# D1H register map
Vendor: Allwinner; File version: 1.0
Registers are 32-bit, read-write, reset 0x0 unless marked. A register's access mark holds for its fields unless they carry their own. Offsets are from the block's base; [hi:lo] are bit positions; {n}, {i} and the like mark numbered series; 'fields as' and 'values as' point back to an identical list.

## TVE — TV Encoder
Base 0x05604000
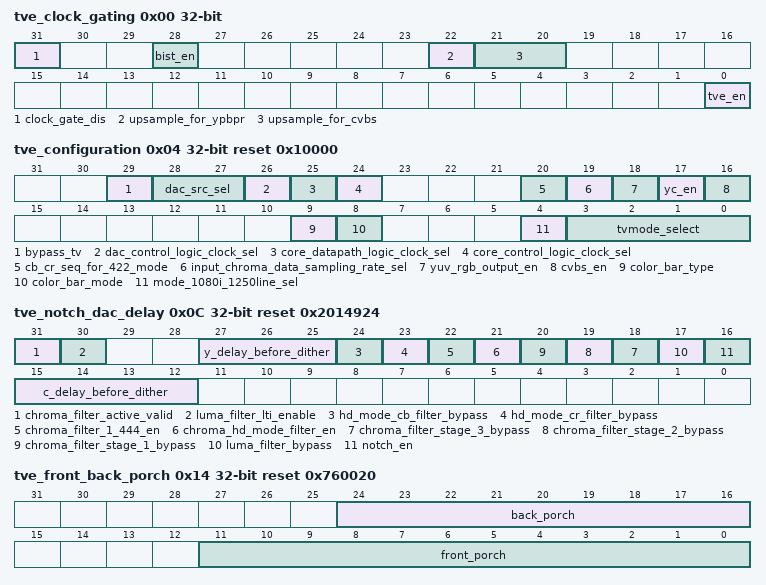
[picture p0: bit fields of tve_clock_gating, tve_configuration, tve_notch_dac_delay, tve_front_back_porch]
0x00 tve_clock_gating — TV Encoder Clock Gating Register
  [31] clock_gate_dis
    0=ENABLE; 1=DISABLE
  [28] bist_en
    0=NORMAL (Normal mode); 1=B_IST (Bist mode)
  [22] upsample_for_ypbpr
    0=1x; 1=X2 (2x)
  [21:20] upsample_for_cvbs
    0=F27M (27 MHz); 1=F54M (54 MHz); 2=F108M (108 MHz); 3=F216M (216 MHz)
  [0] tve_en — Video Encoder enable, default disable, write 1 to take it out of the reset state
    0=DISABLE; 1=ENABLE
0x04 tve_configuration reset 0x10000 — TV Encoder Configuration Register
  [29] bypass_tv
    0=DISABLE; 1=ENABLE
  [28:27] dac_src_sel
    0=TVE (TV Encoder); 1=LCD_CONTROLLER (LCD controller, override all other TV encoder setting, the DAC clock can from LCD controller.); 2=DAC_TEST (DAC test mode, DAC using DAC clock); 3=DAC_TEST_AHB (DAC test mode, DAC using AHB clock)
  [26] dac_control_logic_clock_sel
    0=27M_74_25M (Using 27 MHz clock or 74.25 MHz clock depend on CCU setting); 1=54M_148_5M (Using 54 MHz clock or 148.5 MHz clock depend on CCU setting)
  [25] core_datapath_logic_clock_sel
    values as dac_control_logic_clock_sel
  [24] core_control_logic_clock_sel
    values as dac_control_logic_clock_sel
  [20] cb_cr_seq_for_422_mode
    0=C_B (Cb first); 1=C_R (Cr first)
  [19] input_chroma_data_sampling_rate_sel
    0=4_4_4; 1=4_2_2
  [18] yuv_rgb_output_en
    0=CVBS
  [17] yc_en — S-port Video enable Selection. . This bit selects whether the S-port(Y/C) video output is enabled or disabled.
    0=Y_C (Y/C is disable)
  [16] cvbs_en — Composite video enables selection . This bit selects whether the composite video output (CVBS) is enabled or disabled.
    0=DISABLED (Composite video is disabled, Only Y/C is enabled); 1=ENABLED (Composite video is enabled., CVBS and Y/C are enabled)
  [9] color_bar_type
    0=75/7.5/75/7.5 (NTSC), 100/0/75/0(PAL); 1=100/7.5/100/7.5(NTSC), 100/0/100/0(PAL)
  [8] color_bar_mode — Standard Color bar input selection . This bit selects whether the Video Encoder video data input is replaced by an internal standard color bar generator or not.
    0=D_ISPLAY_E_NGINEER (The Video Encoder input is coming from the Display Engineer); 1=I_NTERNAL_GENERATOR (The Video Encoder input is coming from an internal standard color bar generator.)
  [4] mode_1080i_1250line_sel
    0=1125 Line mode; 1=1250 Line mode
  [3:0] tvmode_select — TVMode_Select . Note: Changing this register value will cause some relative register setting to relative value.
    0=NTSC; 1=PAL
0x08 tve_dac1 — TV Encoder DAC Register1
  [6:4] dac0_src_sel
    0=C_OMPOSITE
0x0C tve_notch_dac_delay reset 0x2014924 (reset mask 0xCFFFFFFF) — TV Encoder Notch and DAC Delay Register
  [31] chroma_filter_active_valid
    0=DISABLE; 1=ENABLE
  [30] luma_filter_lti_enable
    0=DISABLE (Disable Luma filter lti); 1=ENABLE (Enable Luma filter lti)
  [27:25] y_delay_before_dither
  [24] hd_mode_cb_filter_bypass
    0=ENABLE (Bypass Enable); 1=DISABLE (Bypass Disable)
  [23] hd_mode_cr_filter_bypass
    0=ENABLE (Bypass Enable); 1=DISABLE (Bypass Disable)
  [22] chroma_filter_1_444_en
    0=DISABLE (Chroma Filter 1 444 Disable); 1=ENABLE (Chroma Filter 1 444 Enable)
  [21] chroma_hd_mode_filter_en
    0=DISABLE (Chroma HD Filter Disable); 1=ENABLE (Chroma HD Filter Enable)
  [18] chroma_filter_stage_{x}_bypass (x=3,2,1; step 1)
    0=ENABLE (Chroma Filter Stage [i] Enable); 1=BYPASS (Chroma Filter Stage [i] bypass)
  [17] luma_filter_bypass
    0=ENABLE (Luma Filter Enable); 1=BYPASS (Luma Filter bypass)
  [16] notch_en — Luma notch filter on/off selection . Note: This bit selects if the luma notch filter is operating or bypassed.
    0=BYPASSED (The luma notch filter is bypassed); 1=OPERATING (The luma notch filter is operating)
  [15:12] c_delay_before_dither
0x10 tve_chroma_frequency reset 0x21F07C1F — TV Encoder Chroma Frequency Register
  [31:0] chroma_freq — Specify the ratio between the color burst frequency. 32 bits unsigned fraction. The default value is h21f07c1f, which is compatible with NTSC spec.
0x14 tve_front_back_porch reset 0x760020 — TV Encoder Front/Back Porch Register
  [24:16] back_porch — Specify the width of the back porch in encoder clock cycles. Min value is (burst_width+breeze_way+17). 8 bits unsigned integer. . The default value is 118. . For 720p mode, the value is 260. . For 1080i/p mode, the value is 192.
  [11:0] front_porch — Must be even . Specify the width of the front porch in encoder clock cycles. 6 bits unsigned even integer. Allowed range is form 10 to 62. . The default value is 32. . For 1080i mode, the value is 44.
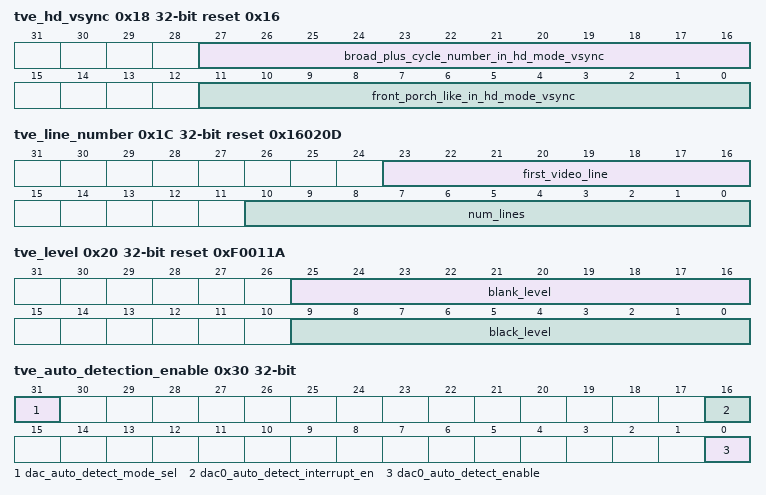
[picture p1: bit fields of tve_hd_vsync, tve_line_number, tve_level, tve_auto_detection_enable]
0x18 tve_hd_vsync reset 0x16 — TV Encoder HD Mode VSYNC Register
  [27:16] broad_plus_cycle_number_in_hd_mode_vsync, [11:0] front_porch_like_in_hd_mode_vsync
0x1C tve_line_number reset 0x16020D — TV Encoder Line Number Register
  [23:16] first_video_line — Specify the index of the first line in a field/frame to have active video. 8 bits unsigned integer. . For interlaced video: When VSync5=B'0', FirstVideoLine is restricted to be greater than 7. When VSync5=B'1', FirstVideoLine is restricted to be greater than 9.
  [10:0] num_lines — Specify the total number of lines in a video frame. 11 bits unsigned integer. Allowed range is 0 to 2048. For interlaced video: When NTSC, and FirstVideoLine is greater than 20, then NumLines is restricted to be greater than 2*(FirstVideoLine+18). . When NTSC, and FirstVideoLine is not greater than 20, then NumLines is restricted to be greater than 77. When PAL, and FirstVideoLine is greater than 22, then NumLines is restricted to be greater than 2*(FirstVideoLine+18). When PAL, and FirstVideoLine is not greater than 22, then NumLines is restricted to be greater than 81. . If NumLines is even, then it is restricted to be divisible by 4. If NumLines is odd, then it is restricted to be divisible by 4 with a remainder of 1.
0x20 tve_level reset 0xF0011A — TV Encoder Level Register
  [25:16] blank_level — Specify the blank level setting for active lines. This is 10 bits unsigned integer. Allowed range is from 0 to 1023.
  [9:0] black_level — Specify the black level setting. This is 10 bits unsigned integer. Allowed range is from 240 to 1023.
0x24 tve_dac2 — TV Encoder DAC Register2
0x30 tve_auto_detection_enable — TV Encoder Auto Detection Enable Register
  [31] dac_auto_detect_mode_sel
    0=O_LD (Old Mode); 1=N_EW (New Mode)
  [16] dac0_auto_detect_interrupt_en
  [0] dac0_auto_detect_enable
0x34 tve_auto_detection_interrupt_status — TV Encoder Auto Detection Interrupt Status Register
  [0] dac0_auto_detect_interrupt_active_flag write-1-clears — Write 1 to inactive DAC0 auto detection interrupt
0x38 tve_auto_detection_status — TV Encoder Auto Detection Status Register
  [1:0] dac0_status ro
    0=U_NCONNECTED; 1=C_ONNECTED; 3=S_HORT_TO_GROUND
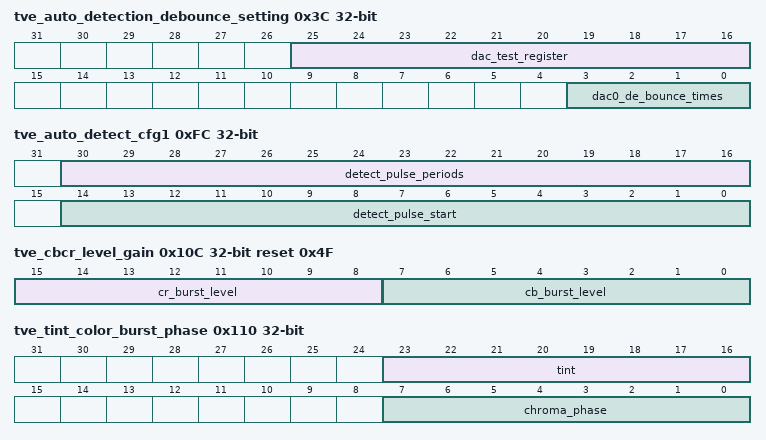
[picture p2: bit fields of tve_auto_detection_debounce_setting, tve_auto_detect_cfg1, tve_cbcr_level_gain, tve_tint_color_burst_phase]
0x3C tve_auto_detection_debounce_setting — TV Encoder Auto Detection De-bounce Setting Register
  [25:16] dac_test_register
  [3:0] dac0_de_bounce_times — The de_bounce time for hot plug detect function.
0xF8 tve_auto_detect_cfg0 — TV Encoder Auto Detect Configuration Register0
  [9:0] detect_pulse_value — Use for DAC data input at auto detect pluse. Set the pulse amplitude.
0xFC tve_auto_detect_cfg1 — TV Encoder Auto Detect Configuration Register1
  [30:16] detect_pulse_periods — Use 32K clock
  [14:0] detect_pulse_start — Detect signal start time
0x100 tve_color_burst_phase_reset_cfg — TV Encoder Color Burst Phase Reset Configuration Register
  [1:0] color_phase_reset — Color burst phase period selection . These bits select the number of fields or lines after which the color burst phase is reset to its initial value as specified by the ChromaPhase parameter, This parameter is application only for interlaced video.
    0=LINE8 (8 field); 1=LINE4 (4 field); 2=LINE2 (2 lines); 3=ONLY_ONCE
0x104 tve_vsync_number — TV Encoder VSYNC Number Register
  [0] vsync5 — VSync5 Number of equalization pulse selection . This bit selects whether the number of equalization pulses is 5 or 6. This parameter is applicable only for interlaced video.
    0=5 equalization pulse(default); 1=6 equalization pulses
0x108 tve_notch_filter_frequency reset 0x2 — TV Encoder Notch Filter Frequency Register
  [2:0] notch_freq — Luma notch filter center frequency selection . These bits select the luma notch filter (which is a band-reject filter) center frequency. In two of the selections, the filter width affects also the selection of the center frequency.
    0=1_1875; 1=1_1406; 2=1.0938. When notch_wide value is B'1' (this selection is proper for CCIR-NTSC), or 1.0000 when notch_wide value is B'0'.; 3=0.9922. This selection is proper for NTSC with square pixels.; 4=0.9531. This selection is proper for PAL with square pixel.; 5=0.8359 when notch_wide value is B'1' (this selection is proper for CCIR-PAL), or 0.7734 when notch_wide value is B'0'; 6=0_7813; 7=0_7188
0x10C tve_cbcr_level_gain reset 0x4F — TV Encoder Cb/Cr Level/Gain Register
  [15:8] cr_burst_level — Specify the amplitude of the Cr burst. 8 bit 2's complement integer. Allowed range is from (-127) to 127.
  [7:0] cb_burst_level — Specify the amplitude of the Cb burst. 8 bit 2's complement integer. Allowed range is from (-127) to 127.
0x110 tve_tint_color_burst_phase — TV Encoder Tint and Color Burst Phase Register
  [23:16] tint — Specify the tint adjustment of the chroma signal for CVBS and Y/C outputs. The adjustment is effected by setting the sub- carrier phase to the value of this parameter. 8.8 bit unsigned fraction. Units are cycles of the color burst frequency.
  [7:0] chroma_phase — Specify the color burst initial phase (ChromaPhase). 8.8 bit unsigned fraction. Units are cycles of the color burst frequency. . The color burst is set to this phase at the first HSYNC and then reset to the same value at further HSYNCs as specified by the CPhaseRset bits of the EncConfig5 parameter (see above)
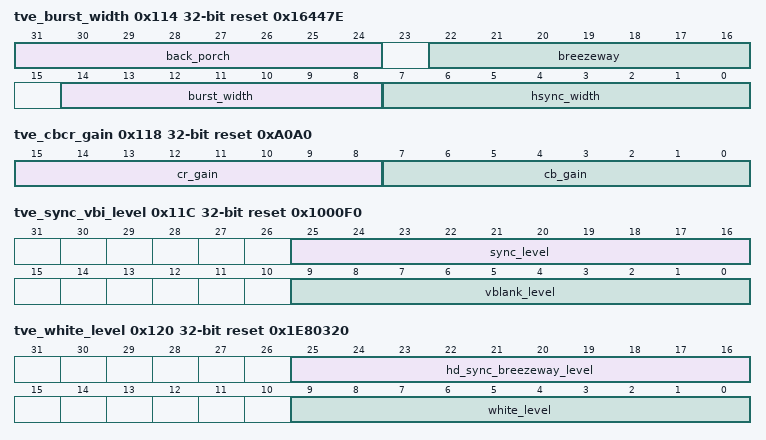
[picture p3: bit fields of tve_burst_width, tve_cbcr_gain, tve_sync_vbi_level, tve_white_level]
0x114 tve_burst_width reset 0x16447E — TV Encoder Burst Width Register
  [31:24] back_porch — Breezeway like in HD mode VSync . For 720p mode, the value is 220 . For 2080i/p mode, the value is 88 (default)
  [22:16] breezeway — Must be even . Specify the width of the breezeway in encoder clock cycles. 5 bit unsigned integer. Allowed range is 0 to 31. . For 1080i mode, the value is 44. . For 1080p mode, the value is 44. . For 720p mode, the value is 40.
  [14:8] burst_width — Specify the width of the color frequency burst in encoder clock cycles. 7 bit unsigned integer. Allowed range is 0 to 127. In hd mode, it is ignored.
  [7:0] hsync_width — Specify the width of the horizontal sync pulse in encoder clock cycles. Min value is 16. Max value is (FrontPorch + ActiveLine - BackPorch). Default value is 126. The sum of HSyncSize and BackPorch is restricted to be divisible by 4. . For 720p mode, the value is 40. . For 1080i/p mode, the value is 44.
0x118 tve_cbcr_gain reset 0xA0A0 — TV Encoder Cb/Cr Gain Register
  [15:8] cr_gain — Specify the Cr color gain. 8-bit unsigned fraction.
  [7:0] cb_gain — Specify the Cb color gain. 8-bit unsigned fraction.
0x11C tve_sync_vbi_level reset 0x1000F0 — TV Encoder Sync and VBI Level Register
  [25:16] sync_level — Specify the sync pulse level setting. 8-bit unsigned integer. Allowed range is from 0 to ABlankLevel-1 or VBlankLevel-1 (whichever is smaller).
  [9:0] vblank_level — Specify the blank level setting for non active lines. 10-bit unsigned integer. Allow range is from 0 to 1023.
0x120 tve_white_level reset 0x1E80320 — TV Encoder White Level Register
  [25:16] hd_sync_breezeway_level — Specify the breezeway level setting. 10-bit unsigned integer. Allowed range is from 0 to 1023.
  [9:0] white_level — Specify the white level setting. 10-bit unsigned integer. Allowed range is from black_level+1 or vbi_blank_level +1 (whichever is greater) to 1023.
0x124 tve_video_active_line reset 0x5A0 — TV Encoder Video Active Line Register
  [11:0] active_line — Specify the width of the video line in encoder clock cycles. 12- bit unsigned multiple of 4 integer. Allowed range is from 0 to 4092.
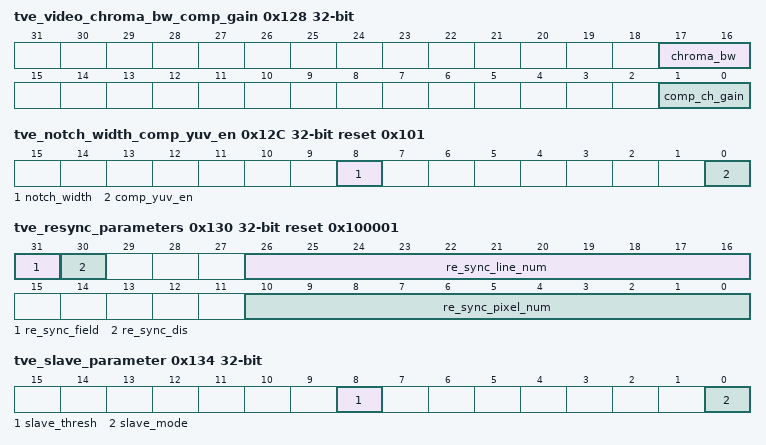
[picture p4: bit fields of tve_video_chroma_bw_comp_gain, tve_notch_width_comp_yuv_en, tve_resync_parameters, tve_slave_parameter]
0x128 tve_video_chroma_bw_comp_gain — TV Encoder Video Chroma BW and CompGain Register
  [17:16] chroma_bw — Chroma filter bandwidth selection . This bit specifies whether the bandwidth of the chroma filter is:
    0=N_ARROW (Narrow width 0.6 MHz); 1=W_IDE (Wide width 1.2 MHz); 2=E_XTRA (Extra width 1.8 MHz); 3=U_LTRA (Ultra width 2.5 MHz)
  [1:0] comp_ch_gain — Chroma gain selection for the composite video signal. . These bits specify the gain of the chroma signal for composing with the luma signal to generate the composite video signal:
    0=100; 1=25; 2=50; 3=75
0x12C tve_notch_width_comp_yuv_en reset 0x101 — TV Encoder Register
  [8] notch_width — Luma notch filter width selection . This bit selects the luma notch filter (which is a band-reject filter) width.
    0=N_ARROW; 1=W_IDE
  [0] comp_yuv_en — This bit selects if the components video output are the RGB components or the YUV components.
    0=RGB (The three component outputs are the RGB components.); 1=YUV (The three component outputs are the YUV components, (i.e. the color conversion unit is bypassed))
0x130 tve_resync_parameters reset 0x100001 — TV Encoder Re-sync Parameters Register
  [31] re_sync_field
  [30] re_sync_dis
    0=ENABLE (Re-Sync Enable); 1=DISABLE (Re-Sync Disable)
  [26:16] re_sync_line_num — Re-sync line number from TCON
  [10:0] re_sync_pixel_num — Re-sync line pixel from TCON
0x134 tve_slave_parameter — TV Encoder Slave Parameter Register
  [8] slave_thresh — Horizontal line adjustment threshold selection . This bit selects whether the number of lines after which the Video Encoder starts the horizontal line length adjustment is slave mode is 0 or 30.
    0=Number of lines is 0; 1=Number of lines is 30
  [0] slave_mode — Slave mode selection . This bit selects whether the Video Encoder is sync slave, partial slave or sync master. It should be set to B'0'.
    0=NOT_FULL_SYNC_SLAVE (The Video Encoder is not a full sync slave (i.e. it is a partial sync slave or a sync master))
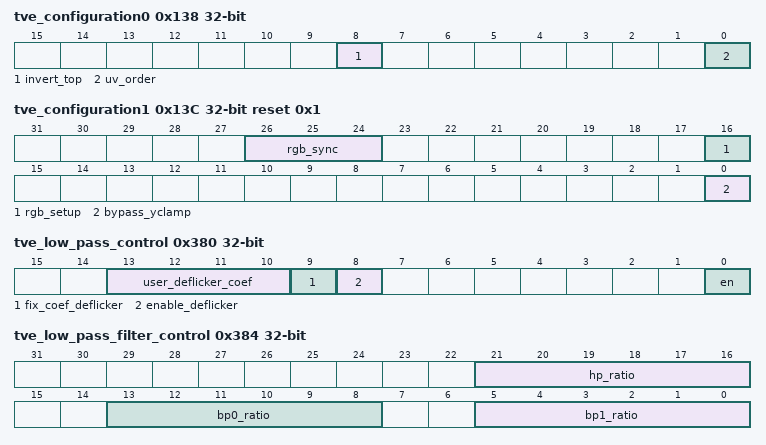
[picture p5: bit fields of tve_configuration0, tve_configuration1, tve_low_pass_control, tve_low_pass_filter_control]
0x138 tve_configuration0 — TV Encoder Configuration Register0
  [8] invert_top — Field parity input signal (top_field) polarity selection. . This bit selects whether the top field is indicated by a high level of the field parity signal or by the low level. The bit is applicable both when the Video Encoder is the sync master and when the Video Encoder is the sync slave.
    0=LOW (Top field is indicated by low level); 1=HIGH (Top field is indicated by high level)
  [0] uv_order — This bit selects if the sample order at the chroma input to the Video Encoder is Cb first (i.e. Cb 0 Cr 0 Cb 1 Cr 1) or Cr first (i.e. Cr 0 Cb 0 Cr 1 Cb 1).
    0=C_B (The chroma sample input order is Cb first); 1=C_R (The chroma sample input order is Cr first)
0x13C tve_configuration1 reset 0x1 — TV Encoder Configuration Register1
  [26:24] rgb_sync — R, G and B signals sync embedding selection. . These bits specify whether the sync signal is added to each of the R, G and B components (b'1') or not (b'0'). The bit[26] specify if the R signal has embedded syncs, the bit[25] specify if the G signal has embedded syncs and the bit[24] specify if the B signal has embedded syncs. When comp_yuv is equal to b'1', these bits are N.A. and should be set to b'000'. When the value is different from b'000', RGB_Setup should be set to b'1'.
  [16] rgb_setup — "Set-up" enable for RGB outputs. This bit specifies if the "set-up" implied value (black_level - blank_level) specified for the CVBS signal is used also for the RGB signals.
    0=NOT_USED (The "set-up" is not used, or i.e. comp_yuv is equal to b'1'.); 1=USED (The implied "set-up" is used for the RGB signals)
  [0] bypass_yclamp — Y input clamping selection . This bit selects whether the Video Encoder Y input is clamped to 64 to 940 or not. When not clamped the expected range is 0 to 1023. The U and V inputs are always clamped to the range 64 to 960.
    0=CLAMPED (The Video Encoder Y input is clamped); 1=NOT_CLAMPED (The Video Encoder Y input is not clamped)
0x380 tve_low_pass_control — TV Encoder Low Pass Control Register
  [13:10] user_deflicker_coef — User_deflicker_coef up: coef/32 . Center: 1-coef/16 . Down: coef/32
  [9] fix_coef_deflicker
    0=A_UTO (Auto deflicker); 1=U_SER (User deflicker)
  [8] enable_deflicker
    0=DISABLE (Disable deflicker); 1=ENABLE (Enable deflicker)
  [0] en — LP function enable
    0=DISABLE; 1=ENABLE
0x384 tve_low_pass_filter_control — TV Encoder Low Pass Filter Control Register
  [21:16] hp_ratio — Default high-pass filter ratio . In two complement, the range is from -31 to 31.
  [13:8] bp0_ratio — Default band-pass filter0 ratio . In two complement, the range is from -31 to 31.
  [5:0] bp1_ratio — Default band-pass filter1 ratio . In two complement, the range is from -31 to 31.
0x388 tve_low_pass_gain — TV Encoder Low Pass Gain Register
  [7:0] gain — Peaking gain setting.
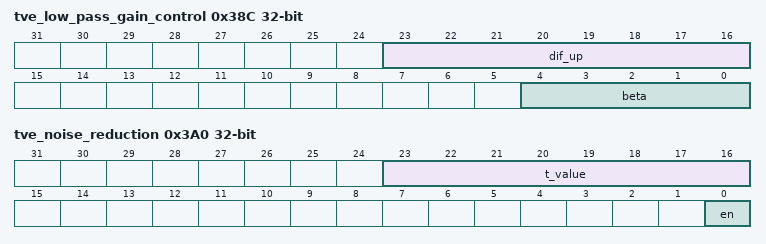
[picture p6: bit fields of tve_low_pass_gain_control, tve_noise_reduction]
0x38C tve_low_pass_gain_control — TV Encoder Low Pass Gain Control Register
  [23:16] dif_up — Gain control: limitation threshold.
  [4:0] beta — Gain control: large gain limitation.
0x390 tve_low_pass_shoot_control — TV Encoder Low Pass Shoot Control Register
  [5:0] neg_gain — Undershoot gain control.
0x394 tve_low_pass_coring — TV Encoder Low Pass Coring Register
  [7:0] corthr — Coring threshold.
0x3A0 tve_noise_reduction — TV Encoder Noise Reduction Register
  [23:16] t_value, [0] en
